# RL7005_IP_SVD register map
Vendor: Realtek
Registers are 32-bit, read-write, reset 0x0 unless marked. A register's access mark holds for its fields unless they carry their own. Offsets are from the block's base; [hi:lo] are bit positions; {n}, {i} and the like mark numbered series.

## SDM_REG
Base 0x4080B000
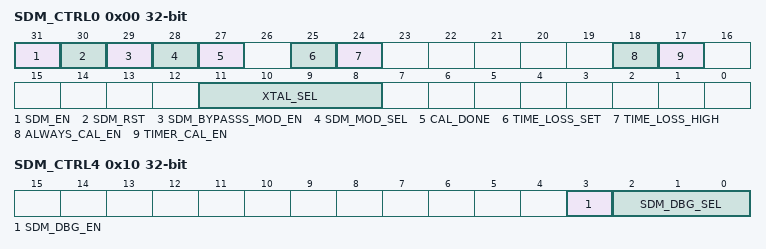
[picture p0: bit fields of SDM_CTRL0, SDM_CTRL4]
0x00 SDM_CTRL0 access per field — SDM Control Register
  [31] SDM_EN rw — Enable SDM
  [30] SDM_RST rw — 0: Reset SDM
  [29] SDM_BYPASSS_MOD_EN rw — Bypass mode enable
  [28] SDM_MOD_SEL rw — 0: Default mode 1: User-defined parameter mode
  [27] CAL_DONE ro
  [25] TIME_LOSS_SET rw — Time loss set 1: User-defined
  [24] TIME_LOSS_HIGH rw — Decide 32k output compensation direction 1: Mask 0: Add
  [18] ALWAYS_CAL_EN rw — 1: Enable always_cal
  [17] TIMER_CAL_EN rw — 1: Enable timer_cal
  [11:8] XTAL_SEL rw — XTAL frequency select, default 40M * 4'h0: XTAL40M * 4'h1: XTAL25M * 4'h4: XTAL20M * 4'h5: XTAL26M * 4'hD: XTAL27M * 4'hE: XTAL24M
0x04 SDM_CTRL1 — Config observed 128K cycle
  [15:0] SDM_OBS_CYC — Set observed 128k cycle, default 1024 128k cycles
0x08 SDM_CTRL2 — Set ref counter value
  [31:0] SDM_OBS_REF_CYC — Set in observed cycles, refer to counters value, default 312500 XTAL cycles
0x0C SDM_CTRL3 — Set XTAL period
  [31:0] XTAL_PERIOD — Set reference xtal period (ns)
0x10 SDM_CTRL4 — SDM Debug Register
  [3] SDM_DBG_EN — 1: Enable SDM debug
  [2:0] SDM_DBG_SEL — Set in observed cycles, refer to counters value
0x14 SDM_CTRL5 — Time loss Set
  [31:0] TIME_LOSS_REG — Source clock time loss every cycle
0x1C SDM_TIMEOUT reset 0x2000000 — Set Timer Trigger Counter Value
  [31:0] TIMEOUT_CNT — Set SDM timer trigger calibration timeout value
0x20 REG_SDM_DUMMY reset 0xFFFF — SDM Dummy Register

## RTC_MISC
Base 0x4080AA80
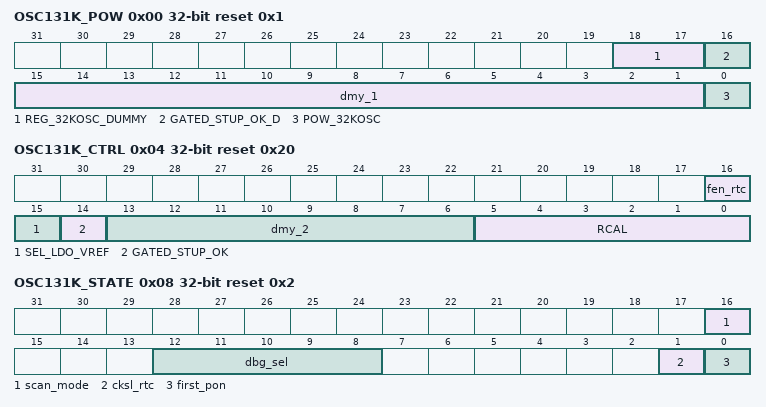
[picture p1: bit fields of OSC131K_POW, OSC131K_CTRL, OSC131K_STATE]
0x00 OSC131K_POW reset 0x1
  [18:17] REG_32KOSC_DUMMY — // [RF][32KOSC] dummy
  [16] GATED_STUP_OK_D — // [RF][32KOSC] dummy
  [15:1] dmy_1
  [0] POW_32KOSC — // [RF][32KOSC] 1'b1 : enable
0x04 OSC131K_CTRL reset 0x20
  [16] fen_rtc — 1: Enable RTC function 0: Disable
  [15] SEL_LDO_VREF — // [RF][32KOSC] REG_CTRL // 0: LDO low valtage setting 1:high voltage
  [14] GATED_STUP_OK — //1'b1 : Close Startup standby current ; //1'b0 : Startup standby current
  [13:6] dmy_2 — // [RF][32KOSC] REG_CTRL // dummy
  [5:0] RCAL — // [RF][32KOSC] REG_CTRL // osc frequency is highier as RCAL's larger
0x08 OSC131K_STATE reset 0x2
  [16] scan_mode — Scan mode enable for RTC domain only .
  [12:8] dbg_sel — rtc debug select for RTC domain PAD
  [1] cksl_rtc — rtc clock select. 0: sdm32k 1: osc131k div4 Note:when aon power off, it will be reset to 1 because sdm is off. when aon power on again , SW must set this bit to 0 after SDM config done.
  [0] first_pon — Default is 0 , after SW write 1 , it will be tie to 1 , until next reset . This indicate RTC first pon state

## DEBUGTIMER_REG
Base 0x40817000
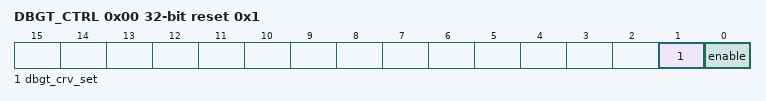
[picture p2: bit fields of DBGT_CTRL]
0x00 DBGT_CTRL access per field reset 0x1 — debugtimer control register
  [1] dbgt_crv_set wo — set dbgt_crv0/1 to dbgtcnt
  [0] enable rw — Debug timer enable. 1: The counter is enabled. 0: The counter is disabled.
0x04 DBGT_CRV0 — debugtimer count register
  [31:0] dbgt_crv0 — dbgtcnt[31:0].Continuing to count from 0 once it's reached 32'Hffffffff
0x08 DBGT_CRV1 — debugtimer count register
  [31:0] dbgt_crv1 — dbgtcnt[63:32].Continuing to count from 0 once it's reached 32'hFFFFFFFF
0x0C DBGT_ATOM_INC ro — debugtimer atom read increase
  [31:0] dbgt_atom_inc — Each read will increase 1 and return to the increased value to bus.
0x10 DBGT_ATOM — debugtimer atom
  [31:0] dbgt_atom — Return the last increased value of atom counter
0x14 DBGT_SCRATCH — debugtimer scratch
  [31:0] dbgt_scratch — Reserved for user use
0x18 REG_DBGTIM_DUMMY reset 0xFFFF — Debug TimerDummy Register

## PMC_TIMER_REG
Base 0x40818000
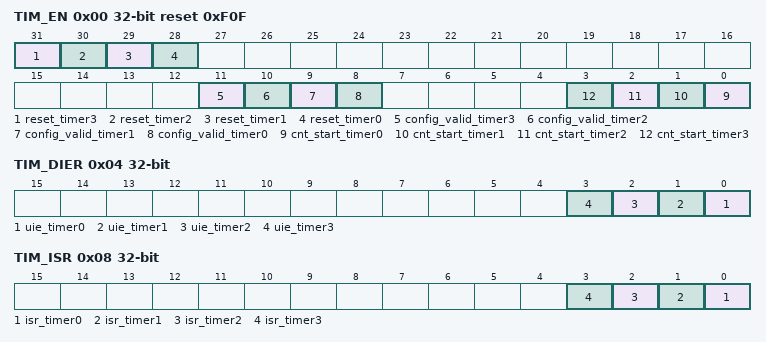
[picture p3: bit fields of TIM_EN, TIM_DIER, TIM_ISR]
0x00 TIM_EN access per field reset 0xF0F — TIM enable register
  [31] reset_timer3 wo — Writing 1 will cause a pulse reset timer1. Please wait for 3 work clk before new timer configuration 1: valid 0: not valid
  [30] reset_timer2 wo — Writing 1 will cause a pulse reset timer1. Please wait for 3 work clk before new timer configuration 1: valid 0: not valid
  [29] reset_timer1 wo — Writing 1 will cause a pulse reset timer1. Please wait for 3 work clk before new timer configuration 1: valid 0: not valid
  [28] reset_timer0 wo — Writing 1 will cause a pulse reset timer0. Please wait for 3 work clk before new timer configuration 1: valid 0: not valid
  [11] config_valid_timer3 ro — TIM_SET configuration valid or not. 1: valid 0: not valid if compare option enable, 1: vaild value is seted 0: set option is on going
  [10] config_valid_timer2 ro — TIM_SET configuration valid or not 1: valid 0: not valid
  [9] config_valid_timer1 ro — TIM_SET configuration valid or not 1: valid 0: not valid
  [8] config_valid_timer0 ro — TIM_SET configuration valid or not 1: valid 0: not valid
  [n] cnt_start_timer{n} rw (n=0..3) — enable the timer{n} counter. 1:enable 0:disable
0x04 TIM_DIER — TIM interupt enable register
  [n] uie_timer{n} (n=0..3) — 1: enable update interrupt 0: disable update interrupt
0x08 TIM_ISR ro — TIM interrupt status register
  [n] isr_timer{n} (n=0..3) — Timer interrupt status 0: no interrupt 1: interrupt occurs Write 1 to clear interrupts in interrupt handler.
{0xC+4i} TIM_CNT{i} ro reset 0xFFFFFFFF (i=0..3) — TIM counter{i}
  [31:0] cnt{i} — counter value, counter will stop automatically when it counts down to zero.
{0x1C+4i} TIM_SET{i} (i=0..3) — TIM set register{i}
  [31:0] tim_set{i} — Set a countdown value. This value come into force when TIM_EN register bit is enabled. counter will count down from this value immediately.
0x2C TIM_com_en reset 0xF — TIM compare register
  [3:0] com_en — enable compare option.The set cnt value takes effect only when it is greater than the actual cnt value 0:disable 1:enable [0] : control tim0 set ...... [3]: control tim3 set
0x30 PMCTIM_DUMMY reset 0xFFFF — PMCTimer Dummy Register
